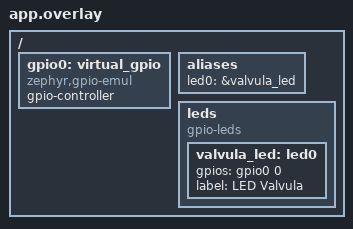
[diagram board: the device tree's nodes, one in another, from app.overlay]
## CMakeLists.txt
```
#-------------------------------------------------------------------------------
# Zephyr Example Application
#
# Copyright (c) 2021 Nordic Semiconductor ASA
# SPDX-License-Identifier: Apache-2.0

cmake_minimum_required(VERSION 3.13.1)
find_package(Zephyr REQUIRED HINTS $ENV{ZEPHYR_BASE})

project(app LANGUAGES C)

target_sources(app PRIVATE src/main.c src/tubulacao.c)

# The code below locates the git index file for this repository and adds it as a dependency for
# the application VERSION file so that if the repo has a new commit added, even if no files in
# the build have changed, the application version file will be regenerated with the new git commit
find_package(Git QUIET)
if(GIT_FOUND)
  execute_process(
    COMMAND ${GIT_EXECUTABLE} rev-parse --absolute-git-dir
    WORKING_DIRECTORY .
    OUTPUT_VARIABLE application_git_dir
    OUTPUT_STRIP_TRAILING_WHITESPACE
    ERROR_STRIP_TRAILING_WHITESPACE
    ERROR_VARIABLE stderr
    RESULT_VARIABLE return_code
  )
  # If there is an error e.g. it is not a git repo, we just silently ignore it and continue
  # without a dependency, this will be the case with freestanding applications.
  if(NOT return_code)
    if(NOT "${stderr}" STREQUAL "")
      message(WARNING "Application build version git rev-parse warned: ${stderr}")
    endif()

    set_property(TARGET app_version_h PROPERTY APP_VERSION_DEPENDS ${application_git_dir}/index)
  endif()
endif()
```

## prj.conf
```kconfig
# Copyright (c) 2021 Nordic Semiconductor ASA
# SPDX-License-Identifier: Apache-2.0
#
# This file contains selected Kconfig options for the application.

# CONFIG_SENSOR=y
# CONFIG_BLINK=y

CONFIG_PRINTK=y
CONFIG_GPIO=y
CONFIG_EMUL=y
CONFIG_GPIO_EMUL=y
```

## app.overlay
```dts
#include <zephyr/dt-bindings/gpio/gpio.h>

/ {
    /* Criando o Controlador GPIO Virtual */
    gpio0: virtual_gpio {
        compatible = "zephyr,gpio-emul";
        gpio-controller;
        #gpio-cells = <2>;
        status = "okay";
    };

    /* Criando o apelido para o código C */
    aliases {
        led0 = &valvula_led;
    };

    /* Criando o pino que simula o Relé/LED */
    leds {
        compatible = "gpio-leds";
        valvula_led: led0 {
            gpios = <&gpio0 0 GPIO_ACTIVE_HIGH>;
            label = "LED Valvula";
        };
    };
};
```

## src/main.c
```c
/*******************************************************************************
 * main.c
 * Arquivo principal de inicialização do sistema Raptor
******************************************************************************/

#include <zephyr/kernel.h>
#include <zephyr/sys/printk.h>
#include "tubulacao.h" // Importação da biblioteca de telemetria e alertas


/*******************************************************************************
 * Função Principal (Entry Point)
*******************************************************************************/
int main(void){
	/* REQUISITO OBRIGATÓRIO DO DESAFIO:
	 * Exibir uma mesagem de inicialização utilizando a API nativa do Zephyr
	 * Foi utilizado printk em substituição ao printf padrão do C por ser
	 * mais leve e otimizado para o kernel do RTOS	
	*/
	printk("\n\nHello World! This is Raptor!\n");

	/* Mantém a thread principal em suspensão (sleep) para não bloquear
	 * outras threads que estão trabalhando em paralelo
	 * As threads de telemetria da tubulação já foram iniciadas atutomaticamente
	 * durante o boot do sistema
	*/
	while(1){
		k_msleep(13000);
	}

	return 0;
}
```

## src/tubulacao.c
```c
/*******************************************************************************
 * tubulacao.c
 * Implementação das threads de monitoramento, telemetria e controle de pressão
*******************************************************************************/

#include <zephyr/kernel.h>
#include <zephyr/sys/printk.h>
#include <zephyr/sys/atomic.h> // Biblioteca de váriaveis atômicas
#include <zephyr/drivers/gpio.h> // Biblioteca para controle de pinos (Hardware)
#include "tubulacao.h" // Importando a definição das estruturas

/// 1 = Valvula de Entrada Aberta (Pressão sobe), 0 = Fechada/Consumo (Pressão desce)
atomic_t estado_valvula = ATOMIC_INIT(1);

/* Inicializa estaticamente uma Message Queue no Zephyr
 * Parâmetros da macro K_MSGQ_DEFINE:
 * 1. Nome da fila: sensor_msgq
 * 2. Tamanho de cada mensagem: sizeof(struct sensor_data_type)
 * 3. Capacidade máxima: 13 mensagens na fila
 * 4. Alinhamnto de memória: 4 bytes (QEMU lê a memoria de 4 em 4 bytes, dessa forma leitura rápida é otimizada)
*/
K_MSGQ_DEFINE(sensor_msgq, sizeof(struct sensor_data_type), 13, 4);

/*Configuração do GPIO
 * Pega o nó da devicetree usando alias 'led0'*/
#define LED0_NODE DT_ALIAS(led0)

//Estrutura de pino baseada em devicetree
static const struct gpio_dt_spec valvula_gpio = GPIO_DT_SPEC_GET(LED0_NODE, gpios);

/*******************************************************************************
 * Máquina de Estados Finita (FSM)
 * Enumeração dos estados do reservatório
*******************************************************************************/
typedef enum{
	ESTADO_NORMAL,
	ESTADO_PRESSAO_ALTA,
	ESTADO_PRESSAO_BAIXA
} estado_reservatorio_t;


/*******************************************************************************
 * THREAD 1: Produtor (simulador do sensor de pressão)
 * * Em Zephyr, a assinatura padrão de uma thread exige três ponteiros genéricos
 * (void *). Como não há passagem de parâmetros externos neste escopo,
 * os argumentos serão recebidos como NULL durante a inicialização
*******************************************************************************/
void sensor_thread(void *p1, void *p2,void *p3){
	struct sensor_data_type data;
	int pressao_atual = 100; // pressão de inicialização
	int variacao = 15; // variação para subir e descer a cada leitura
	
    // Pausa inicial para garantr a exibição prévia dos logs de boot da main
    k_msleep(2000);

    /* NOTA PARA AVALIAÇÃO:
     * Em hardware real, o monitoramento rodaria em loop inifnito (para isso descomentar o while abaixo)
     * Contudo, devido a limitação de sincronismo do emulador QEMU rodando via WSL, que não esta respeitando o k_msleep corretamente,
	 * a execução foi intencionalemnte limitada a 30 iterações (laço for) para garantir que
	 * oslogs de telemetria possam ser lidos com clareza no console
	*/

	// while(1){
    for (int i=0; i < 30; i++){
		/*Lógica de malha fechada
		 * Lê de forma segura o que o FSM decidiu fazer com a válvula */
        if (atomic_get(&estado_valvula) == 1){
            variacao = 15; // se válvula aberta = enchendo, pressão sobe
        } else{ 
            variacao = -15; // se válvula fechada = consumo natural, pressão desce
        }

		pressao_atual += variacao;

		//Trava de segurança para pressão não nagativar
		if (pressao_atual < 0) pressao_atual = 0;

		// Encapsulamento dos dados
		data.pressao_da_agua = pressao_atual;

		/*
		 * Transmite o dado para a Fila de Mensagens. 
		 * Utiliza-se a política K_NO_WAIT (timeout zero) para garantir que a
		 * thread produtora não sofra bloqueio caso a fila esteja cheia.
		*/
		k_msgq_put(&sensor_msgq, &data, K_NO_WAIT);

        // Cadência desimulação 
        k_msleep(3000);

	}

    printk("\n[SISTEMA] Fim da simulacao de leitura (Limite de 30 atingido).\n");
    // se descomentado o while, comentar for e esse printk
}

/*******************************************************************************
 * THREAD 2: Consumidor (lê a fila e opera a FSM)
*******************************************************************************/
void alerta_thread(void *p1, void *p2, void *p3){
	struct sensor_data_type data_recebida;

	// Inicialização segura da FSMcom "memória"
	estado_reservatorio_t estado_atual = ESTADO_NORMAL;

	// Inicializando a GPIO
    // Verifica e configura o hardware apenas uma vez
    if (!gpio_is_ready_dt(&valvula_gpio)) {
        printk("Erro: Dispositivo GPIO nao esta pronto.\n");
        return;
    }
    // Configura o pino como saída de energia, iniciando desligado
    gpio_pin_configure_dt(&valvula_gpio, GPIO_OUTPUT_INACTIVE);

	printk("\n Iniciando monitoramento de pressao via FSM\n\n");

	//Apenas leitura e reação
	while(1){
		/*
		 * Bloqueia a thread atual e aguarda a chegada de novas mesndagens na fila
		 * Foi utilizado K_FOREVER para evitar consumo desnecessário de CPU
		 * enquanto não houver dados disponíveis 
		*/
		k_msgq_get(&sensor_msgq, &data_recebida, K_FOREVER);

		int pressao = data_recebida.pressao_da_agua;
		printk("Leitura do sensor: %d PSI ", pressao);
		
		/**
		 * A Máqquina de Estados avalia as transições com base no estado atual
		 * do reservatório, garantindo que as ações corretivas (como acionar a válvula)
		 * ocorram apenas nas muanças de estado, evitando a emissão de comandos redundates.
		*/
		switch(estado_atual){
            case ESTADO_NORMAL:
                if (pressao >= 130){
                    estado_atual = ESTADO_PRESSAO_ALTA;

                    // FSM Lógica: Fecha a entrada de água (0)
                    atomic_set(&estado_valvula, 0);

                    // GPIO Físico: Corta a energia do pino (Desliga a bomba/relé)
                    gpio_pin_set_dt(&valvula_gpio, 0);

                    printk("MUDANCA: Normal -> ALTO! Fechar entrada de agua.\n\n");
                }else if(pressao <= 70){
                    estado_atual = ESTADO_PRESSAO_BAIXA;

                    // FSM Lógica: Abre a entrada de água (1)
                    atomic_set(&estado_valvula, 1);

                    // GPIO Físico: Manda energia para o pino (Liga a bomba/relé)
                    gpio_pin_set_dt(&valvula_gpio, 1);

                    printk("MUDANCA: Normal -> BAIXO! Ligar bomba/entrada.\n\n");
                }else{
                    printk("Status: Normal.\n\n");
                }
                break;
            
            case ESTADO_PRESSAO_ALTA:
                if (pressao < 130){
                    estado_atual = ESTADO_NORMAL;
                    printk("MUDANCA: Alto -> NORMAL! Pressao caindo...\n\n");
                }
                break;
            
            case ESTADO_PRESSAO_BAIXA:
                if (pressao > 70){
                    estado_atual = ESTADO_NORMAL;
                    printk("MUDANCA: Baixo -> NORMAL! Pressao subindo...\n\n");
                }
                break;
        }
	}
}

/*******************************************************************************
 * Inicialização e Registro no Kernel
 * K_THREAD_DEFINE: Define e inicializa as threads estaticamnete no boot
 * - Stack Size otimizado para 1024 bytes
 * - Nível de prioridade estabelecido em 7 (mediana)
*******************************************************************************/
K_THREAD_DEFINE(sensor_thread_name, 1024, sensor_thread, NULL, NULL, NULL, 7, 0, 0);
K_THREAD_DEFINE(alerta_thread_name, 1024, alerta_thread, NULL, NULL, NULL, 7, 0, 0);
```

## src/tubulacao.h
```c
/*******************************************************************************
 * tubulacao.h
 * Definição das estruturas de dados utilizadas para a telemetria
 * e monitoramento da tubulaçao do reservatóio.
*******************************************************************************/

#ifndef TUBULACAO_H
#define TUBULACAO_H

/*******************************************************************************
 * Estrutura de dados da fila (Payload)
 * Struct para guardar o pacote de dados (mensagem) que trafegará através da Message Queue
*******************************************************************************/
struct sensor_data_type{
	int pressao_da_agua;
};

#endif /* TUBULACAO_H */
```
